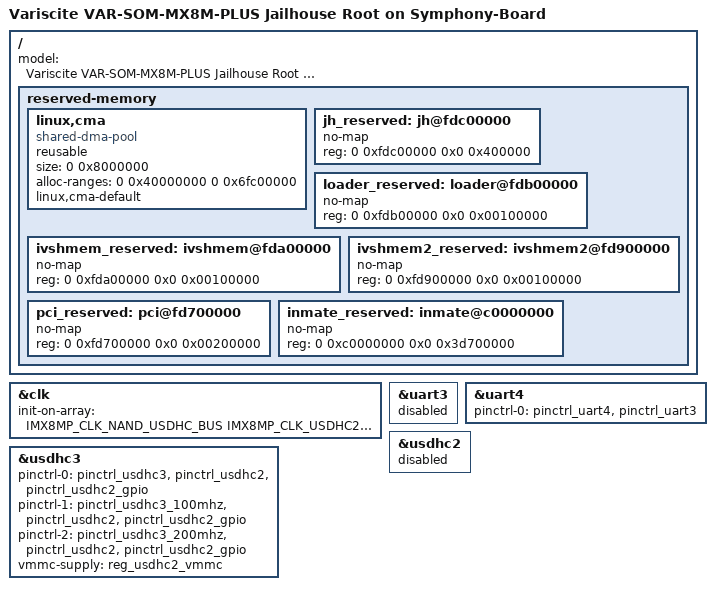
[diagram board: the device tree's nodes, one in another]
// SPDX-License-Identifier: (GPL-2.0+ OR MIT)
/*
 * Copyright 2020 NXP
 * Copyright 2020 - 2023 Variscite
 */

/dts-v1/;

#include "imx8mp-var-som-symphony.dts"

/ {
	model = "Variscite VAR-SOM-MX8M-PLUS Jailhouse Root on Symphony-Board";

	reserved-memory {

		/* 128MB, align to beginning of inmate_reserved */
		linux,cma {
			compatible = "shared-dma-pool";
			reusable;
			size = <0 0x8000000>;
			alloc-ranges = <0 0x40000000 0 0x6fc00000>;
			linux,cma-default;
		};

		jh_reserved: jh@fdc00000 {
			no-map;
			reg = <0 0xfdc00000 0x0 0x400000>;
		};

		loader_reserved: loader@fdb00000 {
			no-map;
			reg = <0 0xfdb00000 0x0 0x00100000>;
		};

		ivshmem_reserved: ivshmem@fda00000 {
			no-map;
			reg = <0 0xfda00000 0x0 0x00100000>;
		};

		ivshmem2_reserved: ivshmem2@fd900000 {
			no-map;
			reg = <0 0xfd900000 0x0 0x00100000>;
		};

		pci_reserved: pci@fd700000 {
			no-map;
			reg = <0 0xfd700000 0x0 0x00200000>;
		};

		inmate_reserved: inmate@c0000000 {
			no-map;
			reg = <0 0xc0000000 0x0 0x3d700000>;
		};
	};
};

&clk {
	init-on-array = <IMX8MP_CLK_NAND_USDHC_BUS
			 IMX8MP_CLK_USDHC2_ROOT
			 IMX8MP_CLK_UART3_ROOT>;
};

/* Disable uart3 from host */
&uart3 {
	status = "disabled";
};

/* Use uart4 device to initialize uart3 pinctrl */
&uart4 {
	pinctrl-0 = <&pinctrl_uart4>, <&pinctrl_uart3>;
};

/* Disable SD Card from host */
&usdhc2 {
	status = "disabled";
};

/* Use EMMC device to initialize SD Card pinctrl and power */
&usdhc3 {
	pinctrl-0 = <&pinctrl_usdhc3>, <&pinctrl_usdhc2>, <&pinctrl_usdhc2_gpio>;
	pinctrl-1 = <&pinctrl_usdhc3_100mhz>, <&pinctrl_usdhc2>, <&pinctrl_usdhc2_gpio>;
	pinctrl-2 = <&pinctrl_usdhc3_200mhz>, <&pinctrl_usdhc2>, <&pinctrl_usdhc2_gpio>;
	vmmc-supply = <&reg_usdhc2_vmmc>;
};
